VERSION ""

NS_ :

BS_:

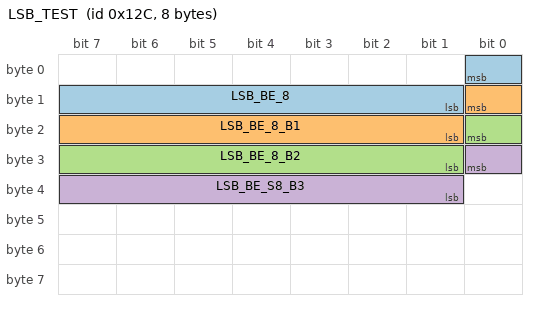
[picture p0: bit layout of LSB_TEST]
BO_ 300 LSB_TEST: 8 Vector__XXX
 SG_ LSB_BE_8 : 0|8@0+ (1,0) [0|255] "" Vector__XXX
 SG_ LSB_BE_8_B1 : 8|8@0+ (1,0) [0|255] "" Vector__XXX
 SG_ LSB_BE_8_B2 : 16|8@0+ (1,0) [0|255] "" Vector__XXX
 SG_ LSB_BE_S8_B3 : 24|8@0- (1,0) [-128|127] "" Vector__XXX
